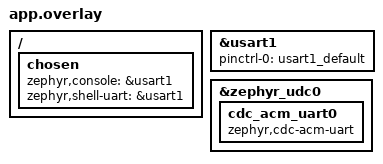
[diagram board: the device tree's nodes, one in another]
/*
 * Copyright (c) 2021 Nordic Semiconductor ASA
 *
 * SPDX-License-Identifier: Apache-2.0
 */

/ {
	chosen {
		zephyr,console = &usart1;
		zephyr,shell-uart = &usart1;
	};
};

&usart1 {
	status = "okay";
	pinctrl-0 = <&usart1_default>;
	pinctrl-names = "default";
};

&zephyr_udc0 {
	cdc_acm_uart0: cdc_acm_uart0 {
		compatible = "zephyr,cdc-acm-uart";
	};
};
